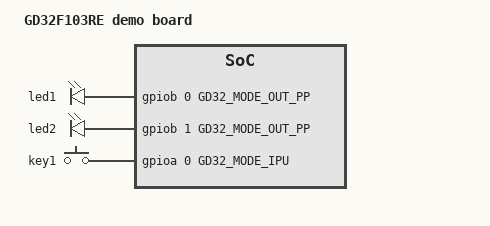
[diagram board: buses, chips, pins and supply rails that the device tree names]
/dts-v1/;

#include "gd32f103re.dtsi"

/ {
	model = "GD32F103RE demo board";
	compatible = "gd,gd32f103re-demo";

	leds {
		compatible = "gd,gpio-leds";
		status = "okay";
		count = <2>;

		led1 {
			gpios = <&gpiob 0 GD32_MODE_OUT_PP>;
			init-level = <GD32_LEVEL_LOW>;
		};

		led2 {
			gpios = <&gpiob 1 GD32_MODE_OUT_PP>;
			init-level = <GD32_LEVEL_LOW>;
		};
	};

	keys {
		compatible = "gd,gpio-keys";
		status = "okay";
		count = <1>;
		key-mode = <KEY_MODE_IRQ>;    /* EXTI 中断(默认); 轮询改 KEY_MODE_POLL + debounce-ms */

		key1 {
			gpios = <&gpioa 0 GD32_MODE_IPU>;
			active-level = <GD32_LEVEL_LOW>;
			trigger = <KEY_TRIG_FALLING>;
		};
	};
};
